AUTOSAR XML (schema 4.0)
package /Systems
  system VehicleSystem
    root-software-compositions:
      root sw composition prototype VehicleSoftwareComposition: software-composition=VehicleTopLevel
    system mapping VehicleSystemMapping
      sw-impl-mappings:
        swc to impl mapping EngineController_Mapping: component=VehicleSoftwareComposition.EngineController, component-implementation=EngineController_Implementation
      sw-mappings:
        swc to ecu mapping EngineController_To_EngineECU: component=VehicleSoftwareComposition.EngineController, ecu-instance=ECU_Engine
        swc to ecu mapping TransmissionController_To_TransmissionECU: component=VehicleSoftwareComposition.TransmissionController, ecu-instance=ECU_Transmission
      data-mappings:
        data-element=EngineController.PP_EngineSpeed.SpeedValue, system-signal=SIG_EngineSpeed
        data-element=ThrottleSensor.PP_ThrottlePosition.ThrottleValue, system-signal=SIG_ThrottlePosition
package /SystemSignals
  system signal SIG_EngineSpeed: init-value=0, length=2, base-type=uint16
  system signal SIG_ThrottlePosition: length=1
  system signal SIG_EngineTemperature: length=2
package /Compositions
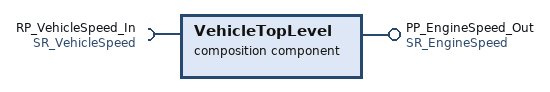
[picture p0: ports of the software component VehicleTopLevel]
  composition sw component type VehicleTopLevel
    4 x component:
      EngineController: type=EngineController
      TransmissionController: type=TransmissionController
      ThrottleSensor: type=ThrottleSensor
      BodyController: type=BodyController
    connect ThrottleSensor.PP_ThrottlePosition -> EngineController.RP_ThrottlePosition
    delegate EngineController.PP_EngineSpeed <-> outer port PP_EngineSpeed_Out
    provide port PP_EngineSpeed_Out: provided-interface=SR_EngineSpeed
    require port RP_VehicleSpeed_In: required-interface=SR_VehicleSpeed
